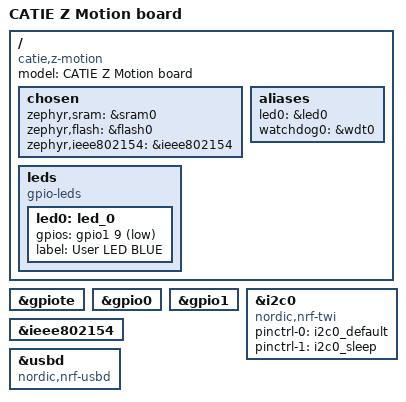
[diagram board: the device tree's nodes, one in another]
/*
 * Copyright (c) 2023 CATIE
 *
 * SPDX-License-Identifier: Apache-2.0
 */

/dts-v1/;
#include <nordic/nrf52833_qiaa.dtsi>
#include "z_motion-pinctrl.dtsi"

/ {
	model = "CATIE Z Motion board";
	compatible = "catie,z-motion";

	chosen {
		zephyr,sram = &sram0;
		zephyr,flash = &flash0;
		zephyr,ieee802154 = &ieee802154;
	};

	leds {
		compatible = "gpio-leds";
		led0: led_0 {
			gpios = <&gpio1 9 GPIO_ACTIVE_LOW>;
			label = "User LED BLUE";
		};
	};

	/* These aliases are provided for compatibility with samples */
	aliases {
		led0 = &led0;
		watchdog0 = &wdt0;
	};
};

&gpiote {
	status = "okay";
};

&gpio0 {
	status = "okay";
};

&gpio1 {
	status = "okay";
};

&i2c0 {
	compatible = "nordic,nrf-twi";
	status = "okay";
	pinctrl-0 = <&i2c0_default>;
	pinctrl-1 = <&i2c0_sleep>;
	pinctrl-names = "default", "sleep";
};

&ieee802154 {
	status = "okay";
};

&usbd {
	compatible = "nordic,nrf-usbd";
	status = "okay";
};
